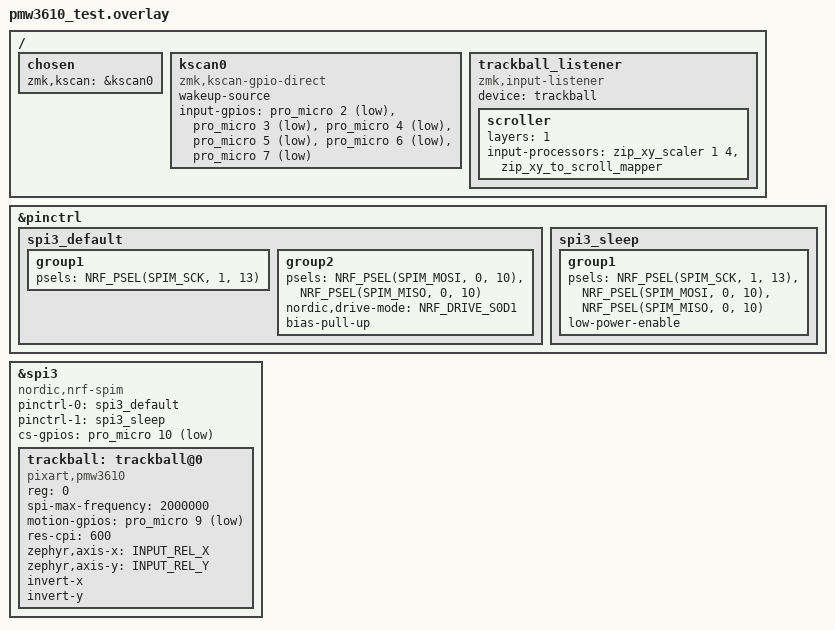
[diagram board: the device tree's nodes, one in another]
#include <zephyr/dt-bindings/input/input-event-codes.h>
#include <input/processors.dtsi>

/*
 * Shield de teste do sensor optico PMW3610DM-SUDU, mouse USB standalone.
 * Ver "pmw3610 esquema eletrico.svg" na raiz do projeto pra fiacao completa.
 *
 * PMW3610 e SPI MEIO-DUPLEX: uma unica linha SDIO faz MOSI e MISO. Por isso
 * NAO da pra usar o &pro_micro_spi padrao (que assume MOSI/MISO em pinos
 * separados) -- este overlay define um barramento SPI3 dedicado, com o
 * MESMO psel em MOSI e MISO. Mesma tecnica ja usada na tela do dongle
 * (splitkb_dongle.overlay), so que aqui os dois psels apontam pro mesmo pino
 * (D16) em vez de dois pinos diferentes.
 *
 *   D15 -> SCLK   D16 -> SDIO (MOSI=MISO)   D10 -> nCS   D9 -> MOTION (irq)
 *   3V3 -> VIN    GND -> GND   nRESET -> nao conectado (driver reseta via SPI)
 */

&pinctrl {
    spi3_default: spi3_default {
        group1 {
            /* SCK: pino de saida "normal", nao compartilhado -- drive padrao. */
            psels = <NRF_PSEL(SPIM_SCK, 1, 13)>;
        };
        group2 {
            /* SDIO (D16): MOSI e MISO no MESMO pino fisico (half-duplex).
             * S0D1 = ativo (drive) so no "0", solto (Hi-Z) no "1", + pull-up.
             * Sem isso, o nRF preenche a fase de leitura com o ORC (0xFF por
             * padrao) com drive FORTE (H0H1, usado por engano aqui antes,
             * copiado da tela do dongle onde MOSI/MISO SAO pinos separados)
             * e sempre vence o sinal fraco do sensor -- por isso a leitura
             * dava sempre 0xFF (o proprio ORC ecoado), nunca o dado real do
             * chip. Com S0D1+pull-up, ao mandar 0xFF (ORC = todos bits 1) o
             * nosso lado solta a linha e o PMW3610 consegue responder.
             */
            psels = <NRF_PSEL(SPIM_MOSI, 0, 10)>,
                    <NRF_PSEL(SPIM_MISO, 0, 10)>;
            nordic,drive-mode = <NRF_DRIVE_S0D1>;
            bias-pull-up;
        };
    };
    spi3_sleep: spi3_sleep {
        group1 {
            psels = <NRF_PSEL(SPIM_SCK, 1, 13)>,
                    <NRF_PSEL(SPIM_MOSI, 0, 10)>,
                    <NRF_PSEL(SPIM_MISO, 0, 10)>;
            low-power-enable;
        };
    };
};

&spi3 {
    status = "okay";
    compatible = "nordic,nrf-spim";
    pinctrl-0 = <&spi3_default>;
    pinctrl-1 = <&spi3_sleep>;
    pinctrl-names = "default", "sleep";
    cs-gpios = <&pro_micro 10 GPIO_ACTIVE_LOW>;    /* D10 = nCS */

    trackball: trackball@0 {
        status = "okay";
        compatible = "pixart,pmw3610";    /* driver NATIVO do Zephyr (drivers/input/input_pmw3610.c),
                                            * nao mais o fork badjeff/zmk-pmw3610-driver ("-alt").
                                            * Init sincrono e mais simples -- trocado em 2026-07-28
                                            * pra diagnosticar o hang silencioso do driver antigo. */
        reg = <0>;
        spi-max-frequency = <2000000>;    /* teto do PMW3610 (datasheet) */
        motion-gpios = <&pro_micro 9 (GPIO_ACTIVE_LOW | GPIO_PULL_UP)>;   /* D9 = MOTION */
        res-cpi = <600>;                  /* 200..3200, passo 200 -- ajustar ao gosto */
        zephyr,axis-x = <INPUT_REL_X>;
        zephyr,axis-y = <INPUT_REL_Y>;
        /* CONFIRMADO por teste (log ao vivo + confirmacao direta): os bits de
         * inversao do proprio sensor funcionam normalmente -- a suspeita
         * anterior de que nao faziam efeito era um .uf2 antigo/errado gravado
         * por engano, nao um bug real do driver/chip. Cursor descia quando
         * devia subir e ia pra esquerda quando devia ir pra direita antes
         * disso. */
        invert-x;
        invert-y;
    };
};

/ {
    /* 6 botoes da trackball, ligacao DIRETA (kscan-gpio-direct) -- sem
     * diodo, cada botao no seu proprio pino (D2..D7, livres -- D9/D10/D15/
     * D16 ja sao do sensor PMW3610 acima). Ver "trackball_botoes esquema
     * eletrico.svg" na raiz do projeto pra fiacao completa.
     * Ordem do array = ordem fisica do assembly() em trackball.scad:
     *   [0]=A1 [1]=A2 [2]=A3 (coluna x=0) [3]=B1 [4]=B2 [5]=B3 (coluna x=-70)
     */
    chosen {
        zmk,kscan = &kscan0;
    };

    kscan0: kscan0 {
        compatible = "zmk,kscan-gpio-direct";
        wakeup-source;
        input-gpios
            = <&pro_micro 2 (GPIO_ACTIVE_LOW | GPIO_PULL_UP)>   /* A1 */
            , <&pro_micro 3 (GPIO_ACTIVE_LOW | GPIO_PULL_UP)>   /* A2 */
            , <&pro_micro 4 (GPIO_ACTIVE_LOW | GPIO_PULL_UP)>   /* A3 */
            , <&pro_micro 5 (GPIO_ACTIVE_LOW | GPIO_PULL_UP)>   /* B1 */
            , <&pro_micro 6 (GPIO_ACTIVE_LOW | GPIO_PULL_UP)>   /* B2 */
            , <&pro_micro 7 (GPIO_ACTIVE_LOW | GPIO_PULL_UP)>   /* B3 */
            ;
    };

    trackball_listener: trackball_listener {
        compatible = "zmk,input-listener";
        device = <&trackball>;

        /* modo SCROLL -- pedido explicito, troca o clique do meio (era
         * &mkp MB3, ver pmw3610_test.keymap) por um &tog 1 (toggle da
         * scroll_layer). Enquanto essa camada estiver ativa, o movimento
         * da bola vira scroll (zip_xy_to_scroll_mapper, input-processor
         * built-in do ZMK) em vez de mover o cursor. */
        scroller {
            layers = <1>;
            /* zip_xy_scaler <multiplicador> <divisor>, ANTES do mapper --
             * reduz o movimento bruto pra 1/4 antes de virar scroll (pedido
             * explicito, "scroll rapido demais"). Ajustar o divisor se
             * precisar mais/menos sensibilidade. */
            input-processors = <&zip_xy_scaler 1 4>, <&zip_xy_to_scroll_mapper>;
        };
    };
};
